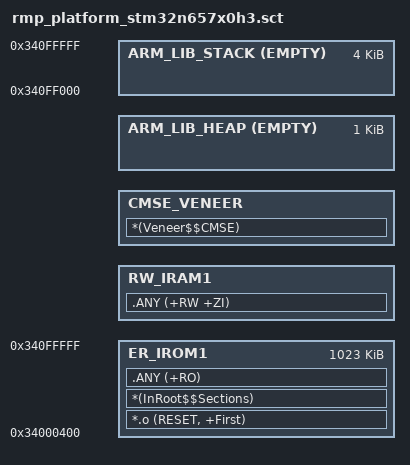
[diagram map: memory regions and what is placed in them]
#! armclang -E --target=arm-arm-none-eabi -mcpu=cortex-m55 -xc

/* Scatter file for the STM32N657X0H3 RAM image (the chip has no internal
   flash; the whole image is downloaded by the debugger into AXISRAM1).
   This mirrors the GNU linker script of the GCCMF project: everything in
   a single region at 0x34000400, boot stack at the top of SRAM1. */

#define __ROM_BASE      0x34000400
#define __ROM_SIZE      0x000FFC00          /* top of SRAM1: 0x34100000 */
#define __STACK_SIZE    0x00001000
#define __HEAP_SIZE     0x00000400
#define __STACK_TOP     ( __ROM_BASE + __ROM_SIZE )

LR_IROM1 __ROM_BASE __ROM_SIZE  {
  ER_IROM1 __ROM_BASE __ROM_SIZE  {
   *.o (RESET, +First)
   *(InRoot$$Sections)
   .ANY (+RO)
  }

  RW_IRAM1 +0  {
   .ANY (+RW +ZI)
  }

  ; CMSE veneers generated by the -mcmse compilation
  CMSE_VENEER +0  {
   *(Veneer$$CMSE)
  }

  ARM_LIB_HEAP  +0 EMPTY __HEAP_SIZE  {
  }

  ARM_LIB_STACK __STACK_TOP EMPTY -__STACK_SIZE  {
  }
}
